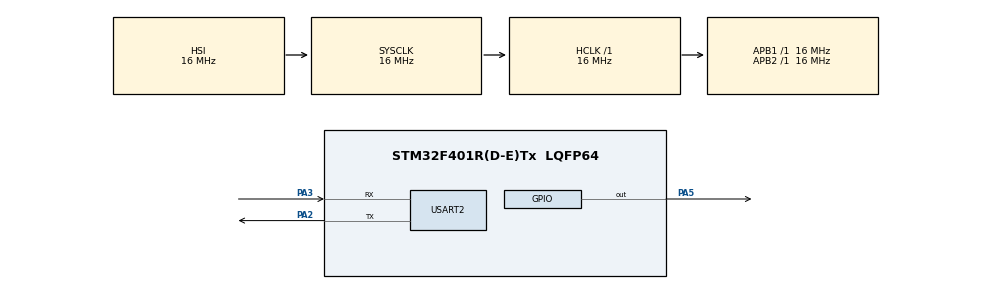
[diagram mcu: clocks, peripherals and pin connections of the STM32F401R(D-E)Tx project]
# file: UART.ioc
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Mcu.Family=STM32F4
Mcu.Name=STM32F401R(D-E)Tx
Mcu.Package=LQFP64
NVIC.PriorityGroup=NVIC_PRIORITYGROUP_4
PA2.Mode=Asynchronous
PA2.Signal=USART2_TX
PA3.Mode=Asynchronous
PA3.Signal=USART2_RX
PA5.Signal=GPIO_Output
ProjectManager.HeapSize=0x200
ProjectManager.StackSize=0x400
ProjectManager.TargetToolchain=STM32CubeIDE
RCC.AHBFreq_Value=16000000
RCC.APB1Freq_Value=16000000
RCC.APB2Freq_Value=16000000
RCC.CortexFreq_Value=16000000
RCC.HSE_VALUE=25000000
RCC.HSI_VALUE=16000000
RCC.LSE_VALUE=32768
RCC.SYSCLKFreq_VALUE=16000000
RCC.VCOOutputFreq_Value=192000000
USART2.Parity=PARITY_NONE
USART2.VirtualMode=VM_ASYNC
USART2.WordLength=WORDLENGTH_8B
board=custom

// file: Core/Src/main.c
/* USER CODE BEGIN Header */
/**
  ******************************************************************************
  * @file           : main.c
  * @brief          : Main program body
  ******************************************************************************
  * @attention
  *
  * Copyright (c) 2023 STMicroelectronics.
  * All rights reserved.
  *
  * This software is licensed under terms that can be found in the LICENSE file
  * in the root directory of this software component.
  * If no LICENSE file comes with this software, it is provided AS-IS.
  *
  ******************************************************************************
  */
/* USER CODE END Header */
#include "main.h"
#include "usart.h"
#include "gpio.h"
#define BUFFER_SIZE 3

/* USER CODE BEGIN Includes */
#include "stm32f4xx_hal.h"
/* USER CODE END Includes */

/* USER CODE BEGIN PTD */

char received_buffer[BUFFER_SIZE];
 uint8_t buffer_index = 0;

/* USER CODE END PTD */

void SystemClock_Config(void);
/* USER CODE BEGIN PFP */
void process_received_data(void);
/* USER CODE END PFP */

int main(void)
{

  /* MCU Configuration--------------------------------------------------------*/

  /* Reset of all peripherals, Initializes the Flash interface and the Systick. */
  HAL_Init();

  /* USER CODE BEGIN Init */
  char data_to_send = 'A';
#define BUFFER_SIZE 4
char rx_buffer[BUFFER_SIZE];
  /* USER CODE END Init */

  /* Configure the system clock */
  SystemClock_Config();

  /* Initialize all configured peripherals */
  MX_GPIO_Init();
  MX_USART2_UART_Init();

  /* Infinite loop */
  /* USER CODE BEGIN WHILE */
  while (1)
  {
	 HAL_UART_Receive(&huart2, (uint8_t *)rx_buffer, 4, HAL_MAX_DELAY);

	 if (strncmp(rx_buffer, "LIGH", 4) == 0){
		 HAL_GPIO_WritePin(GPIOA, GPIO_PIN_5, SET);

	 }
	 else if (strncmp(rx_buffer, "LOW1", 4) == 0){
		 HAL_GPIO_WritePin(GPIOA, GPIO_PIN_5, RESET);
			 }

	 rx_buffer[0]= '\0';

	  /* USER CODE END WHILE */

  }
}

void SystemClock_Config(void)
{
  RCC_OscInitTypeDef RCC_OscInitStruct = {0};
  RCC_ClkInitTypeDef RCC_ClkInitStruct = {0};

  /** Configure the main internal regulator output voltage
  */
  __HAL_RCC_PWR_CLK_ENABLE();
  __HAL_PWR_VOLTAGESCALING_CONFIG(PWR_REGULATOR_VOLTAGE_SCALE2);

  /** Initializes the RCC Oscillators according to the specified parameters
  * in the RCC_OscInitTypeDef structure.
  */
  RCC_OscInitStruct.OscillatorType = RCC_OSCILLATORTYPE_HSI;
  RCC_OscInitStruct.HSIState = RCC_HSI_ON;
  RCC_OscInitStruct.HSICalibrationValue = RCC_HSICALIBRATION_DEFAULT;
  RCC_OscInitStruct.PLL.PLLState = RCC_PLL_NONE;
  if (HAL_RCC_OscConfig(&RCC_OscInitStruct) != HAL_OK)
  {
    Error_Handler();
  }

  /** Initializes the CPU, AHB and APB buses clocks
  */
  RCC_ClkInitStruct.ClockType = RCC_CLOCKTYPE_HCLK|RCC_CLOCKTYPE_SYSCLK
                              |RCC_CLOCKTYPE_PCLK1|RCC_CLOCKTYPE_PCLK2;
  RCC_ClkInitStruct.SYSCLKSource = RCC_SYSCLKSOURCE_HSI;
  RCC_ClkInitStruct.AHBCLKDivider = RCC_SYSCLK_DIV1;
  RCC_ClkInitStruct.APB1CLKDivider = RCC_HCLK_DIV1;
  RCC_ClkInitStruct.APB2CLKDivider = RCC_HCLK_DIV1;

  if (HAL_RCC_ClockConfig(&RCC_ClkInitStruct, FLASH_LATENCY_0) != HAL_OK)
  {
    Error_Handler();
  }
}

/* USER CODE BEGIN 4 */
void process_received_data(void) {
  // Verificar si se recibió el carácter 'L'
  if (received_buffer[0] == 'L') {
    // Encender el LED (asumimos que el LED está conectado al pin GPIO_PIN_13)
    HAL_GPIO_WritePin(GPIOB, GPIO_PIN_13, GPIO_PIN_SET);
  }
}
/* USER CODE END 4 */

void Error_Handler(void)
{
  __disable_irq();
  while (1)
  {
  }
}
